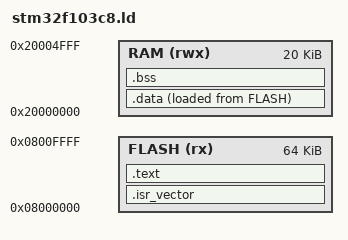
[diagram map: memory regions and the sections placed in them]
ENTRY(Reset_Handler)
MEMORY {
    FLASH (rx) : ORIGIN = 0x08000000, LENGTH = 64K
    RAM (rwx) : ORIGIN = 0x20000000, LENGTH = 20K
}
__stack_top = ORIGIN(RAM) + LENGTH(RAM);
SECTIONS {
    .isr_vector : { KEEP(*(.isr_vector)) } > FLASH
    .text : { *(.text*) *(.rodata*) . = ALIGN(4); } > FLASH
    .data : { __data_start__ = .; *(.data*) . = ALIGN(4); __data_end__ = .; } > RAM AT > FLASH
    __data_load__ = LOADADDR(.data);
    .bss (NOLOAD) : { __bss_start__ = .; *(.bss*) *(COMMON) . = ALIGN(4); __bss_end__ = .; } > RAM
}
